# PIC32CX1025MTSH128S1 register map
Vendor: Microchip Technology; Series: PIC32CXMTSH; File version: 0
CPU: CM4 r0p1, selectable endian, MPU, FPU, 4 interrupt priority bits
Registers are 32-bit, read-write, reset 0x0 unless marked. A register's access mark holds for its fields unless they carry their own. Offsets are from the block's base; [hi:lo] are bit positions; lines under a group give offsets from that group; {n}, {i} and the like mark numbered series; 'fields as' and 'values as' point back to an identical list.

## RTC — Real-time Clock
Base 0x40053100; register names take the prefix RTC_
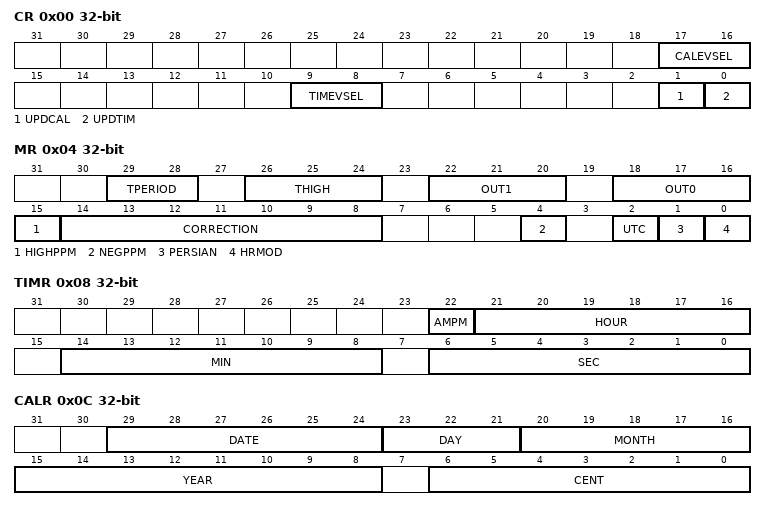
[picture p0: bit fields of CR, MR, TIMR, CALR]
0x00 CR — Control Register
  [17:16] CALEVSEL — Calendar Event Selection
    0=WEEK (Week change (every Monday at time 00:00:00)); 1=MONTH (Month change (every 01 of each month at time 00:00:00)); 2=YEAR (Year change (every January 1 at time 00:00:00))
  [9:8] TIMEVSEL — Time Event Selection
    0=MINUTE (Minute change); 1=HOUR (Hour change); 2=MIDNIGHT (Every day at midnight); 3=NOON (Every day at noon)
  [1] UPDCAL — Update Request Calendar Register
    0=STOP_UPDATE (No effect or, if UPDCAL has been previously written to 1, stops the update procedure.); 1=START_UPDATE (Stops the RTC calendar counting.)
  [0] UPDTIM — Update Request Time Register
    0=STOP_UPDATE (No effect or, if UPDTIM has been previously written to 1, stops the update procedure.); 1=START_UPDATE (Stops the RTC time counting. Second, minute and hour counters can be programmed once this bit is set and acknowledged by the bit ACKUPD of the RTC_SR.)
0x04 MR — Mode Register
  [29:28] TPERIOD — Period of the Output Pulse
    0=P_1S (1 second); 1=P_500MS (500 ms); 2=P_250MS (250 ms); 3=P_125MS (125 ms)
  [26:24] THIGH — High Duration of the Output Pulse
    0=H_31MS (31.2 ms); 1=H_16MS (15.6 ms); 2=H_4MS (3.91 ms); 3=H_976US (976 us); 4=H_488US (488 us); 5=H_122US (122 us); 6=H_30US (30.5 us); 7=H_15US (15.2 us)
  [22:20] OUT1 — RTCOUT1 Output Source Selection
    0=NO_WAVE (No waveform, stuck at '0'); 1=FREQ1HZ (1 Hz square wave); 2=FREQ32HZ (32 Hz square wave); 3=FREQ64HZ (64 Hz square wave); 4=FREQ512HZ (512 Hz square wave); 5=ALARM_TOGGLE (Output toggles when alarm flag rises); 6=ALARM_FLAG (Output is a copy of the alarm flag); 7=PROG_PULSE (Duty cycle programmable pulse)
  [18:16] OUT0 — RTCOUT0 OutputSource Selection
    values as OUT1
  [15] HIGHPPM — HIGH PPM Correction
    0=DISABLED (Lower range ppm correction with accurate correction (below 30ppm correction).); 1=ENABLED (Higher range ppm correction with accurate correction (higher than 30ppm correction).)
  [14:8] CORRECTION — Slow Clock Correction
  [4] NEGPPM — NEGative PPM Correction
    0=DISABLED (Positive correction (the divider will be slightly higher than 32768).); 1=ENABLED (Negative correction (the divider will be slightly lower than 32768).)
  [2] UTC — UTC Time Format
    0=DISABLED (Gregorian or Persian calendar.); 1=ENABLED (UTC format.)
  [1] PERSIAN — PERSIAN Calendar
    0=DISABLED (Gregorian calendar.); 1=ENABLED (Persian calendar.)
  [0] HRMOD — 12-/24-hour Mode
    0=_24HOURS (24-hour mode is selected.); 1=AMPM (12-hour mode is selected.)
0x08 TIMR — Time Register
  [22] AMPM — Ante Meridiem Post Meridiem Indicator
    0=AM; 1=PM
  [21:16] HOUR — Current Hour
  [14:8] MIN — Current Minute
  [6:0] SEC — Current Second
0x08 TIMR_UTC_MODE_MODE (alternate view of TIMR) — Time Register
  [31:0] UTC_TIME — Current UTC Time
0x0C CALR — Calendar Register
  [29:24] DATE — Current Day in Current Month
  [23:21] DAY — Current Day in Current Week
  [20:16] MONTH — Current Month
  [15:8] YEAR — Current Year
  [6:0] CENT — Current Century
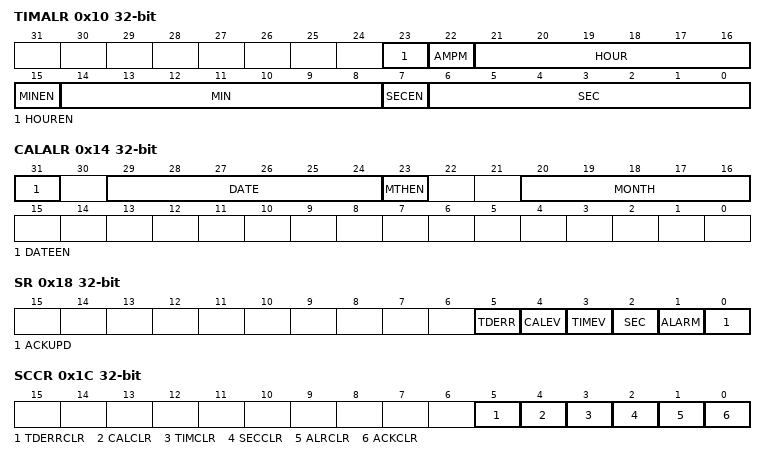
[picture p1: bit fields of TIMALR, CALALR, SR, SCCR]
0x10 TIMALR — Time Alarm Register
  [23] HOUREN — Hour Alarm Enable
    0=DISABLED (The hour-matching alarm is disabled.); 1=ENABLED (The hour-matching alarm is enabled.)
  [22] AMPM — AM/PM Indicator
  [21:16] HOUR — Hour Alarm
  [15] MINEN — Minute Alarm Enable
    0=DISABLED (The minute-matching alarm is disabled.); 1=ENABLED (The minute-matching alarm is enabled.)
  [14:8] MIN — Minute Alarm
  [7] SECEN — Second Alarm Enable
    0=DISABLED (The second-matching alarm is disabled.); 1=ENABLED (The second-matching alarm is enabled.)
  [6:0] SEC — Second Alarm
0x10 TIMALR_UTC_MODE_MODE (alternate view of TIMALR) — Time Alarm Register
  [31:0] UTC_TIME — UTC_TIME Alarm
0x14 CALALR — Calendar Alarm Register
  [31] DATEEN — Date Alarm Enable
    0=DISABLED (The date-matching alarm is disabled.); 1=ENABLED (The date-matching alarm is enabled.)
  [29:24] DATE — Date Alarm
  [23] MTHEN — Month Alarm Enable
    0=DISABLED (The month-matching alarm is disabled.); 1=ENABLED (The month-matching alarm is enabled.)
  [20:16] MONTH — Month Alarm
0x14 CALALR_UTC_MODE_MODE (alternate view of CALALR) — Calendar Alarm Register
  [0] UTCEN — UTC Alarm Enable
    0=DISABLED (The UTC-matching alarm is disabled.); 1=ENABLED (The UTC-matching alarm is enabled.)
0x18 SR ro — Status Register
  [5] TDERR — Time and/or Date Free Running Error
    0=CORRECT (The internal free running counters are carrying valid values since the last read of the Status Register (RTC_SR).); 1=ERR_TIMEDATE (The internal free running counters have been corrupted (invalid date or time, non-BCD values) since the last read and/or they are still invalid.)
  [4] CALEV — Calendar Event
    0=NO_CALEVENT (No calendar event has occurred since the last clear.); 1=CALEVENT (At least one calendar event has occurred since the last clear.)
  [3] TIMEV — Time Event
    0=NO_TIMEVENT (No time event has occurred since the last clear.); 1=TIMEVENT (At least one time event has occurred since the last clear.)
  [2] SEC — Second Event
    0=NO_SECEVENT (No second event has occurred since the last clear.); 1=SECEVENT (At least one second event has occurred since the last clear.)
  [1] ALARM — Alarm Flag
    0=NO_ALARMEVENT (No alarm matching condition occurred.); 1=ALARMEVENT (An alarm matching condition has occurred.)
  [0] ACKUPD — Acknowledge for Update
    0=FREERUN (Time and calendar registers cannot be updated.); 1=UPDATE (Time and calendar registers can be updated.)
0x1C SCCR wo — Status Clear Command Register
  [5] TDERRCLR — Time and/or Date Free Running Error Clear
  [4] CALCLR — Calendar Clear
  [3] TIMCLR — Time Clear
  [2] SECCLR — Second Clear
  [1] ALRCLR — Alarm Clear
  [0] ACKCLR — Acknowledge Clear
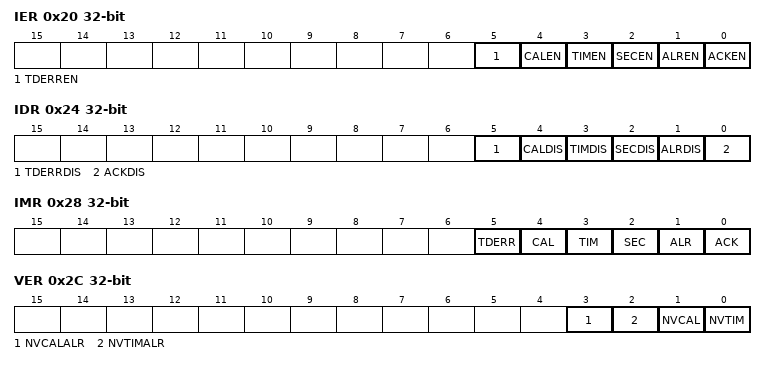
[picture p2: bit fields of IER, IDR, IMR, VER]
0x20 IER wo — Interrupt Enable Register
  [5] TDERREN — Time and/or Date Error Interrupt Enable
  [4] CALEN — Calendar Event Interrupt Enable
  [3] TIMEN — Time Event Interrupt Enable
  [2] SECEN — Second Event Interrupt Enable
  [1] ALREN — Alarm Interrupt Enable
  [0] ACKEN — Acknowledge Update Interrupt Enable
0x24 IDR wo — Interrupt Disable Register
  [5] TDERRDIS — Time and/or Date Error Interrupt Disable
  [4] CALDIS — Calendar Event Interrupt Disable
  [3] TIMDIS — Time Event Interrupt Disable
  [2] SECDIS — Second Event Interrupt Disable
  [1] ALRDIS — Alarm Interrupt Disable
  [0] ACKDIS — Acknowledge Update Interrupt Disable
0x28 IMR ro — Interrupt Mask Register
  [5] TDERR — Time and/or Date Error Mask
  [4] CAL — Calendar Event Interrupt Mask
  [3] TIM — Time Event Interrupt Mask
  [2] SEC — Second Event Interrupt Mask
  [1] ALR — Alarm Interrupt Mask
  [0] ACK — Acknowledge Update Interrupt Mask
0x2C VER ro — Valid Entry Register
  [3] NVCALALR — Non-valid Calendar Alarm
  [2] NVTIMALR — Non-valid Time Alarm
  [1] NVCAL — Non-valid Calendar
  [0] NVTIM — Non-valid Time
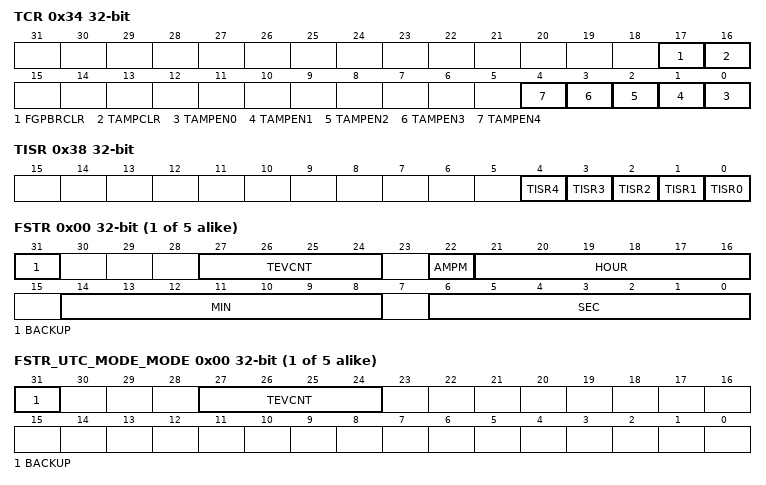
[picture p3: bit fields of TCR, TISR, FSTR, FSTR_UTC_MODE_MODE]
0x34 TCR — Tamper Control Register
  [17] FGPBRCLR — Full GPBR Clear
    0=HALF (If TAMPCLR is set to '1', a tamper event immediately clears GPBR0 to GPBR11.); 1=FULL (If TAMPCLR is set to '1', a tamper event immediately clears all GPBRs.)
  [16] TAMPCLR — Tamper Clear
    0=NOT_ENABLE (A Tamper event does not create an immediate clear on GPBR registers.); 1=ENABLE (Tamper event on TMP0 or TMP4 generates an immediate clear on GPBR registers. The number of cleared GPBR registers depends on the value of FGPBRCLR.)
  [n] TAMPEN{n} (n=0..4) — Timestamping on TMPx input is enabled
    0=TIMESTAMP_OFF (Tamper event on TMPx input is not timestamped.); 1=TIMESTAMP_ON (Tamper event on TMPx input is timestamped.)
0x38 TISR ro — Tamper Input Status Register
  [n] TISR{n} (n=0..4) — TMPx Input Status Register
{0x40+0x10*i} RTC_SUB0[{i}] (i=0..4) group
  0x00 FSTR ro — First Stamping Time Register of Source 0
    [31] BACKUP — System Mode of the Tamper (cleared by reading RTC_LSDRx)
    [27:24] TEVCNT — Tamper Events Counter (cleared by reading RTC_LSDRx)
    [22] AMPM — AM/PM Indicator of the Tamper (cleared by reading RTC_LSDRx)
    [21:16] HOUR — Hours of the Tamper (cleared by reading RTC_LSDRx)
    [14:8] MIN — Minutes of the Tamper (cleared by reading RTC_LSDRx)
    [6:0] SEC — Seconds of the Tamper (cleared by reading RTC_LSDRx)
  0x00 FSTR_UTC_MODE_MODE ro (alternate view of FSTR) — First Stamping Time Register of Source 0
    [31] BACKUP — System Mode of the Tamper (cleared by reading RTC_LSDRx)
    [27:24] TEVCNT — Tamper Events Counter (cleared by reading RTC_LSDRx)
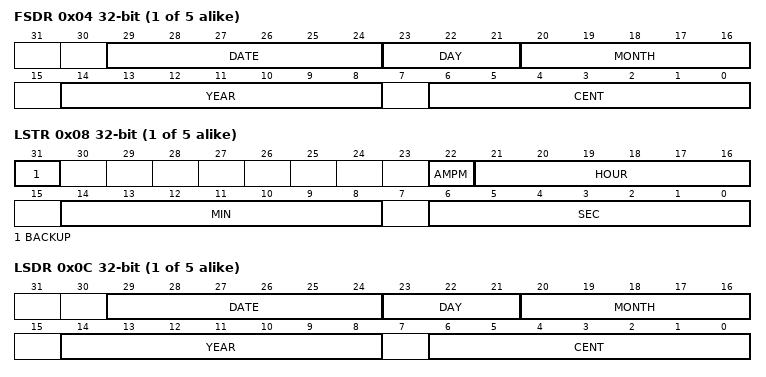
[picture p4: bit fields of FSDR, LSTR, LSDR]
  0x04 FSDR ro — First Stamping Date Register of Source 0
    [29:24] DATE — Date of the Tamper (cleared by reading RTC_LSDRx)
    [23:21] DAY — Day of the Tamper (cleared by reading RTC_LSDRx)
    [20:16] MONTH — Month of the Tamper (cleared by reading RTC_LSDRx)
    [14:8] YEAR — Year of the Tamper (cleared by reading RTC_LSDRx)
    [6:0] CENT — Century of the Tamper (cleared by reading RTC_LSDRx)
  0x04 FSDR_UTC_MODE_MODE ro (alternate view of FSDR) — First Stamping Date Register of Source 0
    [31:0] UTC_TIME — Time of the Tamper (cleared by reading RTC_LSDRx)
  0x08 LSTR ro — Last Stamping Time Register of Source 0
    [31] BACKUP — System Mode of the Tamper (cleared by reading RTC_LSDRx)
    [22] AMPM — AM/PM Indicator of the Tamper (cleared by reading RTC_LSDRx)
    [21:16] HOUR — Hours of the Tamper (cleared by reading RTC_LSDRx)
    [14:8] MIN — Minutes of the Tamper (cleared by reading RTC_LSDRx)
    [6:0] SEC — Seconds of the Tamper (cleared by reading RTC_LSDRx)
  0x08 LSTR_UTC_MODE_MODE ro (alternate view of LSTR) — Last Stamping Time Register of Source 0
    [31] BACKUP — System Mode of the Tamper (cleared by reading RTC_LSDRx)
  0x0C LSDR ro — Last Stamping Date Register of Source 0
    [29:24] DATE — Date of the Tamper (cleared on read)
    [23:21] DAY — Day of the Tamper (cleared on read)
    [20:16] MONTH — Month of the Tamper (cleared on read)
    [14:8] YEAR — Year of the Tamper (cleared on read)
    [6:0] CENT — Century of the Tamper (cleared on read)
  0x0C LSDR_UTC_MODE_MODE ro (alternate view of LSDR) — Last Stamping Date Register of Source 0
    [31:0] UTC_TIME — Time of the Tamper (cleared on read)
